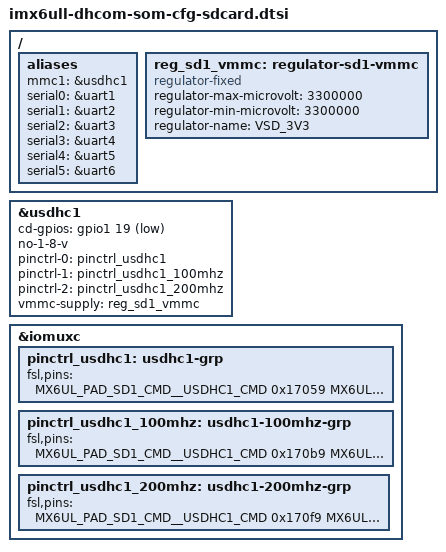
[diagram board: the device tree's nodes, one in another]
// SPDX-License-Identifier: GPL-2.0+ OR BSD-3-Clause
/*
 * Copyright (C) 2023 DH electronics GmbH
 */

/*
 * Special SoM configuration: SD card
 *
 * Enabled:  Micro SD card on module or
 *           external SD card via DHCOM depends on hardware variant
 *           GPIO H and GPIO I will be available
 *           DHCOM UART2 will be available
 * Disabled: WiFi and BT
 */

/*
 * To use usdhc1 as SD card, the WiFi node must be deleted.
 * BT is also not available, so remove BT from the UART node.
 */
/delete-node/ &brcmf;
/delete-node/ &bluetooth;

/ {
	aliases {
		mmc1 = &usdhc1;
		serial0 = &uart1;
		serial1 = &uart2;
		serial2 = &uart3;
		serial3 = &uart4;
		serial4 = &uart5;
		serial5 = &uart6;
	};

	reg_sd1_vmmc: regulator-sd1-vmmc {
		compatible = "regulator-fixed";
		regulator-max-microvolt = <3300000>;
		regulator-min-microvolt = <3300000>;
		regulator-name = "VSD_3V3";
	};
};

/* Micro SD card on module or external SD card via DHCOM */
&usdhc1 {
	/delete-property/ #address-cells;
	/delete-property/ #size-cells;
	/delete-property/ keep-power-in-suspend;
	/delete-property/ mmc-pwrseq;
	/delete-property/ non-removable;
	/delete-property/ wakeup-source;
	cd-gpios = <&gpio1 19 GPIO_ACTIVE_LOW>;
	no-1-8-v;
	pinctrl-0 = <&pinctrl_usdhc1>;
	pinctrl-1 = <&pinctrl_usdhc1_100mhz>;
	pinctrl-2 = <&pinctrl_usdhc1_200mhz>;
	pinctrl-names = "default", "state_100mhz", "state_200mhz";
	vmmc-supply = <&reg_sd1_vmmc>;
	status = "okay";
};

&iomuxc {
	pinctrl_usdhc1: usdhc1-grp {
		fsl,pins = <
			MX6UL_PAD_SD1_CMD__USDHC1_CMD		0x17059
			MX6UL_PAD_SD1_CLK__USDHC1_CLK		0x10059
			MX6UL_PAD_SD1_DATA0__USDHC1_DATA0	0x17059
			MX6UL_PAD_SD1_DATA1__USDHC1_DATA1	0x17059
			MX6UL_PAD_SD1_DATA2__USDHC1_DATA2	0x17059
			MX6UL_PAD_SD1_DATA3__USDHC1_DATA3	0x17059
			MX6UL_PAD_UART1_RTS_B__GPIO1_IO19	0x120b0 /* SD1 CD */
		>;
	};

	pinctrl_usdhc1_100mhz: usdhc1-100mhz-grp {
		fsl,pins = <
			MX6UL_PAD_SD1_CMD__USDHC1_CMD		0x170b9
			MX6UL_PAD_SD1_CLK__USDHC1_CLK		0x100b9
			MX6UL_PAD_SD1_DATA0__USDHC1_DATA0	0x170b9
			MX6UL_PAD_SD1_DATA1__USDHC1_DATA1	0x170b9
			MX6UL_PAD_SD1_DATA2__USDHC1_DATA2	0x170b9
			MX6UL_PAD_SD1_DATA3__USDHC1_DATA3	0x170b9
			MX6UL_PAD_UART1_RTS_B__GPIO1_IO19	0x120b0 /* SD1 CD */

		>;
	};

	pinctrl_usdhc1_200mhz: usdhc1-200mhz-grp {
		fsl,pins = <
			MX6UL_PAD_SD1_CMD__USDHC1_CMD		0x170f9
			MX6UL_PAD_SD1_CLK__USDHC1_CLK		0x100f9
			MX6UL_PAD_SD1_DATA0__USDHC1_DATA0	0x170f9
			MX6UL_PAD_SD1_DATA1__USDHC1_DATA1	0x170f9
			MX6UL_PAD_SD1_DATA2__USDHC1_DATA2	0x170f9
			MX6UL_PAD_SD1_DATA3__USDHC1_DATA3	0x170f9
			MX6UL_PAD_UART1_RTS_B__GPIO1_IO19	0x120b0 /* SD1 CD */
		>;
	};
};
